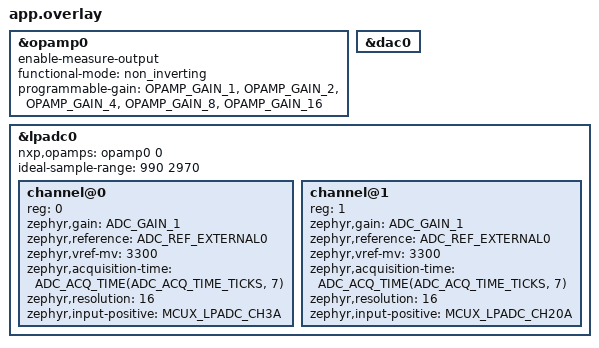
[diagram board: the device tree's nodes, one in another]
/*
 * Copyright 2025 NXP
 *
 * SPDX-License-Identifier: Apache-2.0
 */

#include <zephyr/dt-bindings/adc/adc.h>
#include <zephyr/dt-bindings/adc/mcux-lpadc.h>

&opamp0 {
	#nxp,opamp-cells = <1>;
	enable-measure-output;
	functional-mode = "non_inverting";
	programmable-gain = "OPAMP_GAIN_1",
			"OPAMP_GAIN_2",
			"OPAMP_GAIN_4",
			"OPAMP_GAIN_8",
			"OPAMP_GAIN_16";
};

&dac0 {
	status = "okay";
};

&lpadc0 {
	#address-cells = <1>;
	#size-cells = <0>;

	nxp,opamps = <&opamp0 0>;
	ideal-sample-range = <990 2970>; /* 30% - 90% of ADC full scale with Vref=3300V */

	channel@0 {
		reg = <0>;
		zephyr,gain = "ADC_GAIN_1";
		zephyr,reference = "ADC_REF_EXTERNAL0";
		zephyr,vref-mv = <3300>;
		zephyr,acquisition-time = <ADC_ACQ_TIME(ADC_ACQ_TIME_TICKS, 7)>;
		zephyr,resolution = <16>;
		zephyr,input-positive = <MCUX_LPADC_CH3A>; /* OPAMP output */
	};

	channel@1 {
		reg = <1>;
		zephyr,gain = "ADC_GAIN_1";
		zephyr,reference = "ADC_REF_EXTERNAL0";
		zephyr,vref-mv = <3300>;
		zephyr,acquisition-time = <ADC_ACQ_TIME(ADC_ACQ_TIME_TICKS, 7)>;
		zephyr,resolution = <16>;
		/* DAC output, opamp non-inverting input */
		zephyr,input-positive = <MCUX_LPADC_CH20A>;
	};
};
